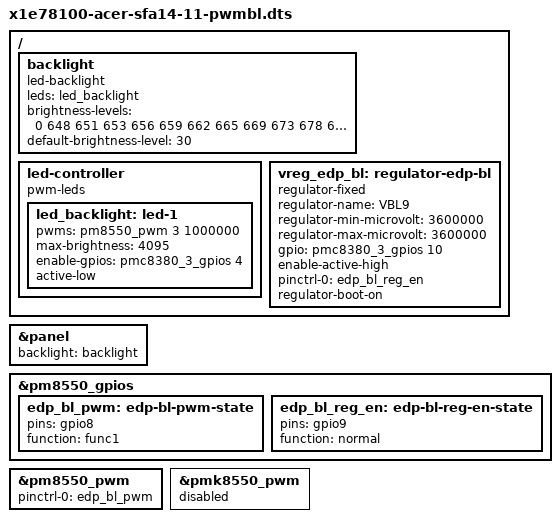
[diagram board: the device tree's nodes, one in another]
// SPDX-License-Identifier: BSD-3-Clause
/*
 * Copyright (c) 2023, Qualcomm Innovation Center, Inc. All rights reserved.
 * Copyright (c) 2025, Linaro Limited
 * Copyright (c) 2025, Zimo Zhang
 */

/dts-v1/;

#include "x1e78100-acer-sfa14-11.dtsi"

/ {
	backlight: backlight {
		compatible = "led-backlight";

		leds = <&led_backlight>;
		brightness-levels = <0 648 651 653 656 659 662 665 669 673 678 683 689 695 702 709 717 725 734 744 754 764 776 787 800 813 827 841 856 872 889 906 923 942 961 981 1002 1023 1045 1068 1091 1116 1141 1167 1193 1221 1249 1278 1308 1338 1370 1402 1435 1469 1504 1539 1576 1613 1651 1690 1730 1771 1812 1855 1898 1942 1988 2034 2081 2129 2177 2227 2278 2329 2382 2436 2490 2546 2602 2659 2718 2777 2837 2898 2961 3024 3088 3154 3220 3287 3355 3425 3495 3566 3639 3712 3787 3862 3939 4016 4095>;
		default-brightness-level = <30>;
	};

	led-controller {
		compatible = "pwm-leds";

		led_backlight: led-1 {
			pwms = <&pm8550_pwm 3 1000000>; // 1kHz
			max-brightness = <4095>;

			enable-gpios = <&pmc8380_3_gpios 4 GPIO_ACTIVE_HIGH>;

			active-low; // Workaround: Qualcomm PMIC doesn't support PWM_POLARITY_INVERTED
		};
	};

	vreg_edp_bl: regulator-edp-bl {
		compatible = "regulator-fixed";

		regulator-name = "VBL9";
		regulator-min-microvolt = <3600000>;
		regulator-max-microvolt = <3600000>;

		gpio = <&pmc8380_3_gpios 10 GPIO_ACTIVE_HIGH>;
		enable-active-high;

		pinctrl-0 = <&edp_bl_reg_en>;
		pinctrl-names = "default";

		regulator-boot-on;
	};
};

&panel {
	backlight = <&backlight>;
};

&pm8550_gpios {
	edp_bl_pwm: edp-bl-pwm-state {
		pins = "gpio8";
		function = "func1"; // Set PinMUX to PWM mode
	};

	edp_bl_reg_en: edp-bl-reg-en-state {
		pins = "gpio9";
		function = "normal";
	};
};

&pm8550_pwm {
	status = "okay";

	pinctrl-0 = <&edp_bl_pwm>;
	pinctrl-names = "default";
};

&pmk8550_pwm {
	status = "disabled";
};
